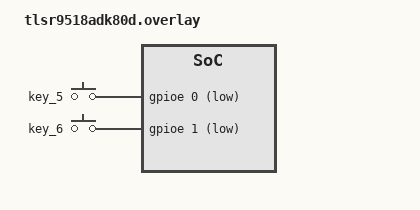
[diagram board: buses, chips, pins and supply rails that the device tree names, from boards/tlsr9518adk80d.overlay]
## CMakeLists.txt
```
#
#    Copyright (c) 2023-2026 Project CHIP Authors
#
#    Licensed under the Apache License, Version 2.0 (the "License");
#    you may not use this file except in compliance with the License.
#    You may obtain a copy of the License at
#
#        http://www.apache.org/licenses/LICENSE-2.0
#
#    Unless required by applicable law or agreed to in writing, software
#    distributed under the License is distributed on an "AS IS" BASIS,
#    WITHOUT WARRANTIES OR CONDITIONS OF ANY KIND, either express or implied.
#    See the License for the specific language governing permissions and
#    limitations under the License.
#

cmake_minimum_required(VERSION 3.20)

get_filename_component(CHIP_ROOT ${CMAKE_CURRENT_SOURCE_DIR}/third_party/connectedhomeip REALPATH)
get_filename_component(TELINK_COMMON ${CHIP_ROOT}/examples/platform/telink REALPATH)
get_filename_component(GEN_DIR ${CHIP_ROOT}/zzz_generated/ REALPATH)

include(${TELINK_COMMON}/common.cmake)
include(${CHIP_ROOT}/config/telink/app/enable-gnu-std.cmake)
include(${CHIP_ROOT}/src/app/chip_data_model.cmake)

project(chip-telink-lock-example)

target_include_directories(app PRIVATE
                           include
                           ${GEN_DIR}/app-common
                           ${GEN_DIR}/lock-app
                           ${TELINK_COMMON}/common/include
                           ${TELINK_COMMON}/util/include
                           ${TELINK_COMMON}/app/include
                           ${TELINK_COMMON}/zephyr_ext)

target_sources(app PRIVATE
               src/AppTask.cpp
               src/AliroDelegate.cpp
               src/ZclCallbacks.cpp
               src/LockManager.cpp
               src/LockSettingsStorage.cpp
               ${CHIP_ROOT}/src/app/persistence/DeferredAttributePersistenceProvider.cpp
               ${TELINK_COMMON}/common/src/mainCommon.cpp
               ${TELINK_COMMON}/common/src/AppTaskCommon.cpp
               ${TELINK_COMMON}/util/src/LEDManager.cpp
               ${TELINK_COMMON}/util/src/ButtonManager.cpp
               ${TELINK_COMMON}/util/src/ThreadUtil.cpp
               ${TELINK_COMMON}/util/src/PWMManager.cpp
               ${TELINK_COMMON}/zephyr_ext/zephyr_key_matrix.c
               ${TELINK_COMMON}/zephyr_ext/zephyr_key_pool.c
               ${TELINK_COMMON}/zephyr_ext/zephyr_led_pool.c
               ${TELINK_COMMON}/zephyr_ext/zephyr_pwm_pool.c
               ${TELINK_COMMON}/zephyr_ext/zephyr_ws2812.c
               ${TELINK_COMMON}/zephyr_ext/zephyr_pm_observer.c)

chip_configure_data_model(app
    ZAP_FILE ${CMAKE_CURRENT_SOURCE_DIR}/../lock-common/lock-app.zap
)

if(CONFIG_BOOTLOADER_MCUBOOT)
  target_sources(app PRIVATE ${TELINK_COMMON}/util/src/OTAUtil.cpp)
endif()

if(CONFIG_OPENTHREAD_SNTP_CLIENT)
  target_sources(app PRIVATE
                   ${TELINK_COMMON}/util/src/ThreadTimeSync.cpp)
endif()
```

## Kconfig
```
#
#    Copyright (c) 2023 Project CHIP Authors
#
#    Licensed under the Apache License, Version 2.0 (the "License");
#    you may not use this file except in compliance with the License.
#    You may obtain a copy of the License at
#
#        http://www.apache.org/licenses/LICENSE-2.0
#
#    Unless required by applicable law or agreed to in writing, software
#    distributed under the License is distributed on an "AS IS" BASIS,
#    WITHOUT WARRANTIES OR CONDITIONS OF ANY KIND, either express or implied.
#    See the License for the specific language governing permissions and
#    limitations under the License.
#
mainmenu "Matter Telink Lock Example Application"

if BOARD_TLSR9528A_RETENTION || BOARD_TLSR9518ADK80D_RETENTION
config COMMON_LIBC_MALLOC_ARENA_SIZE
    default 9216
endif

config SETTINGS_NVS_NAME_CACHE
    default y

config SETTINGS_NVS_NAME_CACHE_SIZE
    default 256

rsource "../../../config/telink/chip-module/Kconfig.defaults"
source "Kconfig.zephyr"
```

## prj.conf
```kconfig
#
#    Copyright (c) 2023-2026 Project CHIP Authors
#
#    Licensed under the Apache License, Version 2.0 (the "License");
#    you may not use this file except in compliance with the License.
#    You may obtain a copy of the License at
#
#        http://www.apache.org/licenses/LICENSE-2.0
#
#    Unless required by applicable law or agreed to in writing, software
#    distributed under the License is distributed on an "AS IS" BASIS,
#    WITHOUT WARRANTIES OR CONDITIONS OF ANY KIND, either express or implied.
#    See the License for the specific language governing permissions and
#    limitations under the License.
#

# This sample uses Kconfig.defaults to set options common for all
# samples. This file should contain only options specific for this sample
# or overrides of default values.

# Enable CHIP
CONFIG_CHIP=y
CONFIG_STD_CPP20=y

# 32774 == 0x8006 (example lock-app)
CONFIG_CHIP_DEVICE_PRODUCT_ID=32774

# Bluetooth Low Energy configuration
CONFIG_BT_DEVICE_NAME="TelinkLock"

# Disable Matter OTA DFU
CONFIG_CHIP_OTA_REQUESTOR=n
CONFIG_CHIP_DEVICE_SOFTWARE_VERSION=1

# Disable CHIP shell support
CONFIG_CHIP_LIB_SHELL=n

# Disable factory data support
CONFIG_CHIP_FACTORY_DATA=n
CONFIG_CHIP_FACTORY_DATA_BUILD=n
CONFIG_CHIP_FACTORY_DATA_MERGE_WITH_FIRMWARE=n

# Enable Power Management
CONFIG_PM=n

# compress ota
CONFIG_COMPRESS_LZMA=n
CONFIG_LZMA=n

# ICD SETTING INFO
CONFIG_CHIP_ICD_SLOW_POLL_INTERVAL=7500
CONFIG_CHIP_ICD_FAST_POLLING_INTERVAL=200
CONFIG_CHIP_ICD_ACTIVE_MODE_THRESHOLD=300
CONFIG_CHIP_ICD_IDLE_MODE_DURATION=900

# Secure programming requires CONFIG_CHIP_FACTORY_DATA and
# CONFIG_CHIP_CERTIFICATION_DECLARATION_STORAGE to be enabled.
CONFIG_SECURE_PROGRAMMING=n

# Enable CHIP-ID via ble
CONFIG_EXPOSE_CHIP_ID_VIA_BLE=n

# Enable Deferred Store Attribute
CONFIG_DEFERRED_ATTR_STORAGE=n
```

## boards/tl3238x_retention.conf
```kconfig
#compress ota
CONFIG_LZMA=y
CONFIG_COMPRESS_LZMA=y
```

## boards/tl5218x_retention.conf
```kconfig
#compress ota
CONFIG_LZMA=n
CONFIG_COMPRESS_LZMA=n

#matter switch mode
# config NORMAL_MODE    0 independent matter mode
# ACTION_DUAL_MODE      1 matter action switch mode ,such as by button
# AUTO_SWITCH_DUAL_MODE 2 matter auto-switch mode ,such as by scan QR code.
CONFIG_DUAL_MODE=0
```

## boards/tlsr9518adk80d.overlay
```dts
/ {
	keys {
		compatible = "gpio-keys";
		key_5: button_5 {
			gpios = <&gpioe 0 (GPIO_PULL_UP | GPIO_ACTIVE_LOW)>;
		};
		key_6: button_6 {
			gpios = <&gpioe 1 (GPIO_PULL_UP | GPIO_ACTIVE_LOW)>;
		};
	};
};

&gpioe {
	interrupts = <38 1>;
	status = "okay";
};
```

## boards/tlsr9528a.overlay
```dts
/ {
	keys {
		compatible = "gpio-keys";
		key_5: button_5 {
			gpios = <&gpiob 6 (GPIO_PULL_UP | GPIO_ACTIVE_LOW)>;
		};
		key_6: button_6 {
			gpios = <&gpiob 7 (GPIO_PULL_UP | GPIO_ACTIVE_LOW)>;
		};
	};
};

&gpiob {
	interrupts = <39 1>;
	status = "okay";
};
```

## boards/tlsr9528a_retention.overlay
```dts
/ {
	keys {
		compatible = "gpio-keys";
		key_5: button_5 {
			gpios = <&gpiob 6 (GPIO_PULL_UP | GPIO_ACTIVE_LOW)>;
		};
		key_6: button_6 {
			gpios = <&gpiob 7 (GPIO_PULL_UP | GPIO_ACTIVE_LOW)>;
		};
	};
};

&gpiob {
	interrupts = <39 1>;
	status = "okay";
};
```

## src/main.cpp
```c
/*
 *
 * SPDX-FileCopyrightText: 2023 Project CHIP Authors
 *
 * SPDX-License-Identifier: Apache-2.0
 */

#include "AppTask.h"

#include <lib/support/CHIPMem.h>
#include <platform/CHIPDeviceLayer.h>

#include <zephyr/kernel.h>

LOG_MODULE_REGISTER(app, CONFIG_CHIP_APP_LOG_LEVEL);

using namespace ::chip;
using namespace ::chip::Inet;
using namespace ::chip::DeviceLayer;

int main(void)
{
    CHIP_ERROR err = CHIP_NO_ERROR;

    err = chip::Platform::MemoryInit();
    if (err != CHIP_NO_ERROR)
    {
        LOG_ERR("MemoryInit fail");
        goto exit;
    }

    err = PlatformMgr().InitChipStack();
    if (err != CHIP_NO_ERROR)
    {
        LOG_ERR("InitChipStack fail");
        goto exit;
    }

    err = PlatformMgr().StartEventLoopTask();
    if (err != CHIP_NO_ERROR)
    {
        LOG_ERR("StartEventLoopTask fail");
        goto exit;
    }

    err = ThreadStackMgr().InitThreadStack();
    if (err != CHIP_NO_ERROR)
    {
        LOG_ERR("InitThreadStack fail");
        goto exit;
    }

#ifdef CONFIG_OPENTHREAD_MTD_SED
    err = ConnectivityMgr().SetThreadDeviceType(ConnectivityManager::kThreadDeviceType_SleepyEndDevice);
#elif CONFIG_OPENTHREAD_MTD
    err = ConnectivityMgr().SetThreadDeviceType(ConnectivityManager::kThreadDeviceType_MinimalEndDevice);
#else
    err = ConnectivityMgr().SetThreadDeviceType(ConnectivityManager::kThreadDeviceType_Router);
#endif
    if (err != CHIP_NO_ERROR)
    {
        LOG_ERR("SetThreadDeviceType fail");
        goto exit;
    }

    err = GetAppTask().StartApp();

exit:
    LOG_ERR("Exit err %" CHIP_ERROR_FORMAT, err.Format());
    return (err == CHIP_NO_ERROR) ? EXIT_SUCCESS : EXIT_FAILURE;
}
```

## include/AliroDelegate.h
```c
/*
 *
 *    Copyright (c) 2026 Project CHIP Authors
 *    All rights reserved.
 *
 *    Licensed under the Apache License, Version 2.0 (the "License");
 *    you may not use this file except in compliance with the License.
 *    You may obtain a copy of the License at
 *
 *        http://www.apache.org/licenses/LICENSE-2.0
 *
 *    Unless required by applicable law or agreed to in writing, software
 *    distributed under the License is distributed on an "AS IS" BASIS,
 *    WITHOUT WARRANTIES OR CONDITIONS OF ANY KIND, either express or implied.
 *    See the License for the specific language governing permissions and
 *    limitations under the License.
 */

#pragma once

#include <AppConfig.h>
#include <app/clusters/door-lock-server/door-lock-delegate.h>
#include <app/clusters/door-lock-server/door-lock-server.h>

class AliroDelegate : public chip::app::Clusters::DoorLock::Delegate
{
public:
    static AliroDelegate & GetInstance() { return sInstance; }

    AliroDelegate(const AliroDelegate &)             = delete;
    AliroDelegate & operator=(const AliroDelegate &) = delete;

    // DoorLock::Delegate interface
    CHIP_ERROR GetAliroReaderVerificationKey(chip::MutableByteSpan & verificationKey) override;
    CHIP_ERROR GetAliroReaderGroupIdentifier(chip::MutableByteSpan & groupIdentifier) override;
    CHIP_ERROR GetAliroReaderGroupSubIdentifier(chip::MutableByteSpan & groupSubIdentifier) override;
    CHIP_ERROR GetAliroExpeditedTransactionSupportedProtocolVersionAtIndex(size_t index,
                                                                           chip::MutableByteSpan & protocolVersion) override;
    CHIP_ERROR GetAliroGroupResolvingKey(chip::MutableByteSpan & groupResolvingKey) override;
    CHIP_ERROR GetAliroSupportedBLEUWBProtocolVersionAtIndex(size_t index, chip::MutableByteSpan & protocolVersion) override;
    uint8_t GetAliroBLEAdvertisingVersion() override;
    uint16_t GetNumberOfAliroCredentialIssuerKeysSupported() override;
    uint16_t GetNumberOfAliroEndpointKeysSupported() override;
    CHIP_ERROR SetAliroReaderConfig(const chip::ByteSpan & signingKey, const chip::ByteSpan & verificationKey,
                                    const chip::ByteSpan & groupIdentifier,
                                    const chip::Optional<chip::ByteSpan> & groupResolvingKey) override;
    CHIP_ERROR ClearAliroReaderConfig() override;

    // Aliro credential storage — called from LockManager
    static bool IsAliroCredentialType(CredentialTypeEnum type);
    bool GetAliroCredential(uint16_t index, CredentialTypeEnum type, EmberAfPluginDoorLockCredentialInfo & out);
    bool SetAliroCredential(uint16_t index, chip::FabricIndex creator, chip::FabricIndex modifier, DlCredentialStatus status,
                            CredentialTypeEnum type, const chip::ByteSpan & data);

private:
    AliroDelegate();

    CHIP_ERROR CopyProtocolVersionIntoSpan(uint16_t protocolVersionValue, chip::MutableByteSpan & protocolVersion);

    // Aliro provisioning state
    uint8_t mAliroReaderVerificationKey[chip::app::Clusters::DoorLock::kAliroReaderVerificationKeySize];
    uint8_t mAliroReaderGroupIdentifier[chip::app::Clusters::DoorLock::kAliroReaderGroupIdentifierSize];
    uint8_t mAliroReaderGroupSubIdentifier[chip::app::Clusters::DoorLock::kAliroReaderGroupSubIdentifierSize];
    uint8_t mAliroGroupResolvingKey[chip::app::Clusters::DoorLock::kAliroGroupResolvingKeySize];
    bool mAliroStateInitialized = false;

    // Aliro credential storage (in-memory; Aliro keys are not persisted to NVM)
    static constexpr size_t kAliroCredentialMaxSize = 65;

    struct CredentialSlot
    {
        DlCredentialStatus status             = DlCredentialStatus::kAvailable;
        chip::FabricIndex createdBy           = 0;
        chip::FabricIndex lastModifiedBy      = 0;
        size_t dataSize                       = 0;
        uint8_t data[kAliroCredentialMaxSize] = { 0 };
    };

    CredentialSlot * SlotArrayForType(CredentialTypeEnum type);

    CredentialSlot mIssuerKeys[APP_MAX_CREDENTIAL];
    CredentialSlot mEvictableEndpointKeys[APP_MAX_CREDENTIAL];
    CredentialSlot mNonEvictableEndpointKeys[APP_MAX_CREDENTIAL];

    static AliroDelegate sInstance;
};
```

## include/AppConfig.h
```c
/*
 *
 *    Copyright (c) 2023 Project CHIP Authors
 *    All rights reserved.
 *
 *    Licensed under the Apache License, Version 2.0 (the "License");
 *    you may not use this file except in compliance with the License.
 *    You may obtain a copy of the License at
 *
 *        http://www.apache.org/licenses/LICENSE-2.0
 *
 *    Unless required by applicable law or agreed to in writing, software
 *    distributed under the License is distributed on an "AS IS" BASIS,
 *    WITHOUT WARRANTIES OR CONDITIONS OF ANY KIND, either express or implied.
 *    See the License for the specific language governing permissions and
 *    limitations under the License.
 */

#pragma once

// ---- Lock Example App Config ----

#define LOCK_MANAGER_CONFIG_USE_NVM_CREDENTIAL_STORAGE 1
#define LOCK_MANAGER_ACTUATOR_MOVEMENT_TIME_MS 2000

#define APP_MAX_USERS 10
#define APP_MAX_CREDENTIAL 10
#define APP_MAX_WEEKDAY_SCHEDULE_PER_USER 10
#define APP_MAX_YEARDAY_SCHEDULE_PER_USER 10
#define APP_MAX_HOLYDAY_SCHEDULE_PER_USER 10

#define APP_MAX_SCHEDULES_TOTAL 100

#define APP_DEFAULT_USERS_COUNT 5
#define APP_DEFAULT_CREDENTIAL_COUNT 5
#define APP_DEFAULT_WEEKDAY_SCHEDULE_PER_USER_COUNT 5
#define APP_DEFAULT_YEARDAY_SCHEDULE_PER_USER_COUNT 5
#define APP_DEFAULT_HOLYDAY_SCHEDULE_PER_USER_COUNT 5

#define APP_SET_NETWORK_COMM_ENDPOINT_SEC 0
```

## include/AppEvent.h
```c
/*
 *
 *    Copyright (c) 2023 Project CHIP Authors
 *    All rights reserved.
 *
 *    Licensed under the Apache License, Version 2.0 (the "License");
 *    you may not use this file except in compliance with the License.
 *    You may obtain a copy of the License at
 *
 *        http://www.apache.org/licenses/LICENSE-2.0
 *
 *    Unless required by applicable law or agreed to in writing, software
 *    distributed under the License is distributed on an "AS IS" BASIS,
 *    WITHOUT WARRANTIES OR CONDITIONS OF ANY KIND, either express or implied.
 *    See the License for the specific language governing permissions and
 *    limitations under the License.
 */

#pragma once

#include <cstdint>

struct AppEvent;
typedef void (*EventHandler)(AppEvent *);

class LEDWidget;

struct AppEvent
{
    enum AppEventTypes
    {
        kEventType_Button = 0,
        kEventType_Timer,
        kEventType_UpdateLedState,
        kEventType_IdentifyStart,
        kEventType_IdentifyStop,
        kEventType_Lighting,
        kEventType_Install,
    };

    uint16_t Type;

    union
    {
        struct
        {
            uint8_t Action;
        } ButtonEvent;
        struct
        {
            void * Context;
        } TimerEvent;
        struct
        {
            LEDWidget * LedWidget;
        } UpdateLedStateEvent;
    };

    EventHandler Handler;
};
```

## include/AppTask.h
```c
/*
 *
 *    Copyright (c) 2023 Project CHIP Authors
 *    All rights reserved.
 *
 *    Licensed under the Apache License, Version 2.0 (the "License");
 *    you may not use this file except in compliance with the License.
 *    You may obtain a copy of the License at
 *
 *        http://www.apache.org/licenses/LICENSE-2.0
 *
 *    Unless required by applicable law or agreed to in writing, software
 *    distributed under the License is distributed on an "AS IS" BASIS,
 *    WITHOUT WARRANTIES OR CONDITIONS OF ANY KIND, either express or implied.
 *    See the License for the specific language governing permissions and
 *    limitations under the License.
 */

#pragma once

#include "AppConfig.h"
#include "AppTaskCommon.h"
#include "LockManager.h"

#define APP_ERROR_EVENT_QUEUE_FAILED CHIP_APPLICATION_ERROR(0x01)
#define APP_ERROR_CREATE_TASK_FAILED CHIP_APPLICATION_ERROR(0x02)
#define APP_ERROR_UNHANDLED_EVENT CHIP_APPLICATION_ERROR(0x03)
#define APP_ERROR_CREATE_TIMER_FAILED CHIP_APPLICATION_ERROR(0x04)
#define APP_ERROR_START_TIMER_FAILED CHIP_APPLICATION_ERROR(0x05)
#define APP_ERROR_STOP_TIMER_FAILED CHIP_APPLICATION_ERROR(0x06)
#define APP_ERROR_ALLOCATION_FAILED CHIP_APPLICATION_ERROR(0x07)

class AppTask : public AppTaskCommon
{
private:
    friend AppTask & GetAppTask(void);
    friend class AppTaskCommon;

    CHIP_ERROR Init(void);
    void LinkButtons(ButtonManager & buttonManager);
    void LinkLeds(LedManager & ledManager);

    static void LockActionEventHandler(AppEvent * event);
    static void LockStateChanged(LockManager::State_t state);
    static void LockJammedEventHandler(void);
    static void LockJammedActionHandler(AppEvent * aEvent);
    static void LockStateEventHandler(void);
    static void LockStateActionHandler(AppEvent * aEvent);

    static AppTask sAppTask;
};

inline AppTask & GetAppTask(void)
{
    return AppTask::sAppTask;
}
```

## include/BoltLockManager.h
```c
/*
 *
 * SPDX-FileCopyrightText: 2023 Project CHIP Authors
 *
 * SPDX-License-Identifier: Apache-2.0
 */

#pragma once

#include <app/clusters/door-lock-server/door-lock-server.h>
#include <lib/core/ClusterEnums.h>
#include <lib/support/ScopedBuffer.h>

#include <zephyr/kernel.h>

#include <cstdint>
#include <vector>

// Maximum number of credentials per user supported by lock
#define CONFIG_LOCK_NUM_CREDENTIALS_PER_USER (2)
// Maximum number of users supported by lock
#define CONFIG_LOCK_NUM_USERS (5)
// Maximum number of credentials supported by lock
#define CONFIG_LOCK_NUM_CREDENTIALS (10)

struct LockCredentialInfo;

#define CONFIG_LOCK_CREDENTIAL_INFO_MAX_DATA_SIZE (20)
#define CONFIG_LOCK_CREDENTIAL_INFO_MAX_TYPES (6)

class AppEvent;

class BoltLockManager
{
public:
    BoltLockManager() :
        mCredentials(CONFIG_LOCK_CREDENTIAL_INFO_MAX_TYPES, std::vector<LockCredentialInfo>(CONFIG_LOCK_NUM_CREDENTIALS + 1))
    {}
    static constexpr size_t kMaxCredentialLength = 128;

    enum class State : uint8_t
    {
        kLockingInitiated = 0,
        kLockingCompleted,
        kUnlockingInitiated,
        kUnlockingCompleted,
    };

    struct UserData
    {
        char mName[DOOR_LOCK_USER_NAME_BUFFER_SIZE];
        CredentialStruct mCredentials[CONFIG_LOCK_NUM_CREDENTIALS_PER_USER];
    };

    struct CredentialData
    {
        chip::Platform::ScopedMemoryBuffer<uint8_t> mSecret;
    };

    using OperationSource     = chip::app::Clusters::DoorLock::OperationSourceEnum;
    using StateChangeCallback = void (*)(State, OperationSource);

    static constexpr uint32_t kActuatorMovementTimeMs = 2000;

    void Init(StateChangeCallback callback);

    State GetState() const { return mState; }
    bool IsLocked() const { return mState == State::kLockingCompleted; }

    bool GetUser(uint16_t userIndex, EmberAfPluginDoorLockUserInfo & user) const;
    bool SetUser(uint16_t userIndex, chip::FabricIndex creator, chip::FabricIndex modifier, const chip::CharSpan & userName,
                 uint32_t uniqueId, UserStatusEnum userStatus, UserTypeEnum userType, CredentialRuleEnum credentialRule,
                 const CredentialStruct * credentials, size_t totalCredentials);

    bool GetCredential(uint16_t credentialIndex, CredentialTypeEnum credentialType,
                       EmberAfPluginDoorLockCredentialInfo & credential) const;
    bool SetCredential(uint16_t credentialIndex, chip::FabricIndex creator, chip::FabricIndex modifier,
                       DlCredentialStatus credentialStatus, CredentialTypeEnum credentialType,
                       const chip::ByteSpan & credentialData);

    bool ValidatePIN(const Optional<chip::ByteSpan> & pinCode, OperationErrorEnum & err) const;

    void Lock(OperationSource source);
    void Unlock(OperationSource source);

private:
    void SetState(State state, OperationSource source);

    static void ActuatorTimerEventHandler(k_timer * timer);
    static void ActuatorAppEventHandler(const AppEvent & aEvent);
    friend BoltLockManager & BoltLockMgr();

    State mState                             = State::kLockingCompleted;
    StateChangeCallback mStateChangeCallback = nullptr;
    OperationSource mActuatorOperationSource = OperationSource::kButton;
    k_timer mActuatorTimer                   = {};

    UserData mUserData[CONFIG_LOCK_NUM_USERS];
    EmberAfPluginDoorLockUserInfo mUsers[CONFIG_LOCK_NUM_USERS] = {};

    struct LockCredentialInfo
    {
        DlCredentialStatus status;
        CredentialTypeEnum credentialType;
        chip::FabricIndex createdBy;
        chip::FabricIndex modifiedBy;
        uint8_t credentialData[CONFIG_LOCK_CREDENTIAL_INFO_MAX_TYPES];
        size_t credentialDataSize;
    };
    std::vector<std::vector<LockCredentialInfo>> mCredentials;

    static BoltLockManager sLock;
};

inline BoltLockManager & BoltLockMgr()
{
    return BoltLockManager::sLock;
}
```

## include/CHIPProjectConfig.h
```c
/*
 *
 *    Copyright (c) 2023 Project CHIP Authors
 *    All rights reserved.
 *
 *    Licensed under the Apache License, Version 2.0 (the "License");
 *    you may not use this file except in compliance with the License.
 *    You may obtain a copy of the License at
 *
 *        http://www.apache.org/licenses/LICENSE-2.0
 *
 *    Unless required by applicable law or agreed to in writing, software
 *    distributed under the License is distributed on an "AS IS" BASIS,
 *    WITHOUT WARRANTIES OR CONDITIONS OF ANY KIND, either express or implied.
 *    See the License for the specific language governing permissions and
 *    limitations under the License.
 */

/**
 *    @file
 *          Example project configuration file for CHIP.
 *
 *          This is a place to put application or project-specific overrides
 *          to the default configuration values for general CHIP features.
 *
 */

#pragma once

// Use a default pairing code if one hasn't been provisioned in flash.
#define CHIP_DEVICE_CONFIG_USE_TEST_SETUP_PIN_CODE 20202021
#define CHIP_DEVICE_CONFIG_USE_TEST_SETUP_DISCRIMINATOR 0xF00

// Enable `Extension` attribute of ACL Cluster as required by door locks
#define CHIP_CONFIG_ENABLE_ACL_EXTENSIONS 1
```

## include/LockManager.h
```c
/*
 *
 *    Copyright (c) 2023 Project CHIP Authors
 *    All rights reserved.
 *
 *    Licensed under the Apache License, Version 2.0 (the "License");
 *    you may not use this file except in compliance with the License.
 *    You may obtain a copy of the License at
 *
 *        http://www.apache.org/licenses/LICENSE-2.0
 *
 *    Unless required by applicable law or agreed to in writing, software
 *    distributed under the License is distributed on an "AS IS" BASIS,
 *    WITHOUT WARRANTIES OR CONDITIONS OF ANY KIND, either express or implied.
 *    See the License for the specific language governing permissions and
 *    limitations under the License.
 */

#pragma once
#include <app/clusters/door-lock-server/door-lock-server.h>

#include <stdbool.h>
#include <stdint.h>
#include <zephyr/kernel.h>

#include <AppConfig.h>
#include <AppEventCommon.h>

#include <lib/core/CHIPError.h>

struct WeekDaysScheduleInfo
{
    DlScheduleStatus status = DlScheduleStatus::kAvailable;
    EmberAfPluginDoorLockWeekDaySchedule schedule;
};

struct YearDayScheduleInfo
{
    DlScheduleStatus status = DlScheduleStatus::kAvailable;
    EmberAfPluginDoorLockYearDaySchedule schedule;
};

struct HolidayScheduleInfo
{
    DlScheduleStatus status = DlScheduleStatus::kAvailable;
    EmberAfPluginDoorLockHolidaySchedule schedule;
};

namespace TelinkDoorLock {
namespace ResourceRanges {
// Used to size arrays
static constexpr uint8_t kMaxCredentialSize  = 20;
static constexpr uint8_t kNumCredentialTypes = 6;

} // namespace ResourceRanges

namespace LockInitParams {

struct LockParam
{
    // Read from zap attributes
    uint16_t numberOfUsers                  = 0;
    uint8_t numberOfCredentialsPerUser      = 0;
    uint8_t numberOfWeekdaySchedulesPerUser = 0;
    uint8_t numberOfYeardaySchedulesPerUser = 0;
    uint8_t numberOfHolidaySchedules        = 0;
};

class ParamBuilder
{
public:
    ParamBuilder & SetNumberOfUsers(uint16_t numberOfUsers)
    {
        lockParam_.numberOfUsers = numberOfUsers;
        return *this;
    }
    ParamBuilder & SetNumberOfCredentialsPerUser(uint8_t numberOfCredentialsPerUser)
    {
        lockParam_.numberOfCredentialsPerUser = numberOfCredentialsPerUser;
        return *this;
    }
    ParamBuilder & SetNumberOfWeekdaySchedulesPerUser(uint8_t numberOfWeekdaySchedulesPerUser)
    {
        lockParam_.numberOfWeekdaySchedulesPerUser = numberOfWeekdaySchedulesPerUser;
        return *this;
    }
    ParamBuilder & SetNumberOfYeardaySchedulesPerUser(uint8_t numberOfYeardaySchedulesPerUser)
    {
        lockParam_.numberOfYeardaySchedulesPerUser = numberOfYeardaySchedulesPerUser;
        return *this;
    }
    ParamBuilder & SetNumberOfHolidaySchedules(uint8_t numberOfHolidaySchedules)
    {
        lockParam_.numberOfHolidaySchedules = numberOfHolidaySchedules;
        return *this;
    }
    LockParam GetLockParam() { return lockParam_; }

private:
    LockParam lockParam_;
};

} // namespace LockInitParams
} // namespace TelinkDoorLock

using namespace ::chip;
using namespace TelinkDoorLock::ResourceRanges;

class LockManager
{
public:
    enum Action_t
    {
        LOCK_ACTION = 0,
        UNLOCK_ACTION,
        UNBOLT_ACTION,

        INVALID_ACTION
    } Action;

    enum State_t
    {
        kState_LockInitiated = 0,
        kState_LockCompleted,
        kState_UnlockInitiated,
        kState_UnlockCompleted,
        kState_UnlatchInitiated,
        kState_UnlatchCompleted,
        kState_NotFulyLocked
    } State;

    using StateChangeCallback = void (*)(State_t);
    using OperationSource     = chip::app::Clusters::DoorLock::OperationSourceEnum;

    CHIP_ERROR Init(chip::app::DataModel::Nullable<chip::app::Clusters::DoorLock::DlLockState> state,
                    TelinkDoorLock::LockInitParams::LockParam lockParam, StateChangeCallback callback);

    bool LockAction(int32_t appSource, Action_t aAction, OperationSource source, chip::EndpointId endpointId);

    bool LockAction(int32_t appSource, Action_t aAction, OperationSource source, chip::EndpointId endpointId,
                    OperationErrorEnum & err, const Nullable<chip::FabricIndex> & fabricIdx = NullNullable,
                    const Nullable<chip::NodeId> & nodeId = NullNullable, const Optional<chip::ByteSpan> & pinCode = NullNullable);

    bool IsLocked() const { return mState == State_t::kState_LockCompleted; }

    State_t getLockState() { return mState; }

    bool GetUser(chip::EndpointId endpointId, uint16_t userIndex, EmberAfPluginDoorLockUserInfo & user);
    bool SetUser(chip::EndpointId endpointId, uint16_t userIndex, chip::FabricIndex creator, chip::FabricIndex modifier,
                 const chip::CharSpan & userName, uint32_t uniqueId, UserStatusEnum userStatus, UserTypeEnum usertype,
                 CredentialRuleEnum credentialRule, const CredentialStruct * credentials, size_t totalCredentials);

    bool GetCredential(chip::EndpointId endpointId, uint16_t credentialIndex, CredentialTypeEnum credentialType,
                       EmberAfPluginDoorLockCredentialInfo & credential);

    bool SetCredential(chip::EndpointId endpointId, uint16_t credentialIndex, chip::FabricIndex creator, chip::FabricIndex modifier,
                       DlCredentialStatus credentialStatus, CredentialTypeEnum credentialType,
                       const chip::ByteSpan & credentialData);

    DlStatus GetWeekdaySchedule(chip::EndpointId endpointId, uint8_t weekdayIndex, uint16_t userIndex,
                                EmberAfPluginDoorLockWeekDaySchedule & schedule);

    DlStatus SetWeekdaySchedule(chip::EndpointId endpointId, uint8_t weekdayIndex, uint16_t userIndex, DlScheduleStatus status,
                                DaysMaskMap daysMask, uint8_t startHour, uint8_t startMinute, uint8_t endHour, uint8_t endMinute);

    DlStatus GetYeardaySchedule(chip::EndpointId endpointId, uint8_t yearDayIndex, uint16_t userIndex,
                                EmberAfPluginDoorLockYearDaySchedule & schedule);

    DlStatus SetYeardaySchedule(chip::EndpointId endpointId, uint8_t yearDayIndex, uint16_t userIndex, DlScheduleStatus status,
                                uint32_t localStartTime, uint32_t localEndTime);

    DlStatus GetHolidaySchedule(chip::EndpointId endpointId, uint8_t holidayIndex, EmberAfPluginDoorLockHolidaySchedule & schedule);

    DlStatus SetHolidaySchedule(chip::EndpointId endpointId, uint8_t holidayIndex, DlScheduleStatus status, uint32_t localStartTime,
                                uint32_t localEndTime, OperatingModeEnum operatingMode);

    bool IsValidUserIndex(uint16_t userIndex);
    bool IsValidCredentialIndex(uint16_t credentialIndex, CredentialTypeEnum type);
    bool IsValidCredentialType(CredentialTypeEnum type);
    bool IsValidWeekdayScheduleIndex(uint8_t scheduleIndex);
    bool IsValidYeardayScheduleIndex(uint8_t scheduleIndex);
    bool IsValidHolidayScheduleIndex(uint8_t scheduleIndex);

    const char * lockStateToString(DlLockState lockState) const;

private:
    friend LockManager & LockMgr();
    State_t mState                           = kState_NotFulyLocked;
    StateChangeCallback mStateChangeCallback = nullptr;
    OperationSource mActuatorOperationSource = OperationSource::kButton;
    k_timer mActuatorTimer                   = {};

    bool setLockState(chip::EndpointId endpointId, DlLockState lockState, OperationSource source, OperationErrorEnum & err,
                      const Nullable<chip::FabricIndex> & fabricIdx, const Nullable<chip::NodeId> & nodeId,
                      const Optional<chip::ByteSpan> & pin);

    static void ActuatorTimerEventHandler(k_timer * timer);
    static void ActuatorAppEventHandler(const AppEvent & event);

#if !LOCK_MANAGER_CONFIG_USE_NVM_CREDENTIAL_STORAGE
    EmberAfPluginDoorLockUserInfo mLockUsers[APP_MAX_USERS];
    EmberAfPluginDoorLockCredentialInfo mLockCredentials[kNumCredentialTypes][APP_MAX_CREDENTIAL];
    WeekDaysScheduleInfo mWeekdaySchedule[APP_MAX_USERS][APP_MAX_WEEKDAY_SCHEDULE_PER_USER];
    YearDayScheduleInfo mYeardaySchedule[APP_MAX_USERS][APP_MAX_YEARDAY_SCHEDULE_PER_USER];
    HolidayScheduleInfo mHolidaySchedule[APP_MAX_HOLYDAY_SCHEDULE_PER_USER];

    char mUserNames[MATTER_ARRAY_SIZE(mLockUsers)][DOOR_LOCK_MAX_USER_NAME_SIZE];
    uint8_t mCredentialData[kNumCredentialTypes][APP_MAX_CREDENTIAL][kMaxCredentialSize];
    CredentialStruct mCredentials[APP_MAX_USERS][APP_MAX_CREDENTIAL];
#endif

    static LockManager sLock;
    TelinkDoorLock::LockInitParams::LockParam LockParams;
};

inline LockManager & LockMgr()
{
    return LockManager::sLock;
}
```

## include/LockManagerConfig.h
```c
/*
 *
 *    Copyright (c) 2023 Project CHIP Authors
 *    All rights reserved.
 *
 *    Licensed under the Apache License, Version 2.0 (the "License");
 *    you may not use this file except in compliance with the License.
 *    You may obtain a copy of the License at
 *
 *        http://www.apache.org/licenses/LICENSE-2.0
 *
 *    Unless required by applicable law or agreed to in writing, software
 *    distributed under the License is distributed on an "AS IS" BASIS,
 *    WITHOUT WARRANTIES OR CONDITIONS OF ANY KIND, either express or implied.
 *    See the License for the specific language governing permissions and
 *    limitations under the License.
 */

#define LOCK_MANAGER_CONFIG_USE_NVM_CREDENTIAL_STORAGE  0
```

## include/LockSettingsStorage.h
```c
/*
 *
 *    Copyright (c) 2023 Project CHIP Authors
 *    All rights reserved.
 *
 *    Licensed under the Apache License, Version 2.0 (the "License");
 *    you may not use this file except in compliance with the License.
 *    You may obtain a copy of the License at
 *
 *        http://www.apache.org/licenses/LICENSE-2.0
 *
 *    Unless required by applicable law or agreed to in writing, software
 *    distributed under the License is distributed on an "AS IS" BASIS,
 *    WITHOUT WARRANTIES OR CONDITIONS OF ANY KIND, either express or implied.
 *    See the License for the specific language governing permissions and
 *    limitations under the License.
 */

#include <../Zephyr/ZephyrConfig.h>
#include <AppConfig.h>
#include <LockManager.h>

#if LOCK_MANAGER_CONFIG_USE_NVM_CREDENTIAL_STORAGE
namespace chip {
namespace DeviceLayer {
namespace Internal {

class LockSettingsStorage : ZephyrConfig
{
public:
    static const char * kConfigKey_LockUser[APP_MAX_USERS];
    static const char * kConfigKey_LockUserName[APP_MAX_USERS];
    static const char * kConfigKey_UserCredentials[APP_MAX_CREDENTIAL];
    static const char * kConfigKey_WeekDaySchedules[APP_MAX_USERS][APP_MAX_WEEKDAY_SCHEDULE_PER_USER];
    static const char * kConfigKey_YearDaySchedules[APP_MAX_USERS][APP_MAX_YEARDAY_SCHEDULE_PER_USER];
    static const char * kConfigKey_HolidaySchedules[APP_MAX_HOLYDAY_SCHEDULE_PER_USER];

    static const char * kConfigKey_CredentialPin[APP_MAX_CREDENTIAL];
    static const char * kConfigKey_CredentialFace[APP_MAX_CREDENTIAL];
    static const char * kConfigKey_CredentialFingerprint[APP_MAX_CREDENTIAL];
    static const char * kConfigKey_CredentialFingervein[APP_MAX_CREDENTIAL];
    static const char * kConfigKey_CredentialRfid[APP_MAX_CREDENTIAL];

    static const char * kConfigKey_CredentialData[APP_MAX_CREDENTIAL];
    static const char * kConfigKey_CredentialDataPin[APP_MAX_CREDENTIAL];
    static const char * kConfigKey_CredentialDataFace[APP_MAX_CREDENTIAL];
    static const char * kConfigKey_CredentialDataFingerprint[APP_MAX_CREDENTIAL];
    static const char * kConfigKey_CredentialDataFingerVein[APP_MAX_CREDENTIAL];
    static const char * kConfigKey_CredentialDataRfid[APP_MAX_CREDENTIAL];
};
} // namespace Internal
} // namespace DeviceLayer
} // namespace chip

#endif
```

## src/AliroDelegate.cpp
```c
/*
 *
 *    Copyright (c) 2026 Project CHIP Authors
 *    All rights reserved.
 *
 *    Licensed under the Apache License, Version 2.0 (the "License");
 *    you may not use this file except in compliance with the License.
 *    You may obtain a copy of the License at
 *
 *        http://www.apache.org/licenses/LICENSE-2.0
 *
 *    Unless required by applicable law or agreed to in writing, software
 *    distributed under the License is distributed on an "AS IS" BASIS,
 *    WITHOUT WARRANTIES OR CONDITIONS OF ANY KIND, either express or implied.
 *    See the License for the specific language governing permissions and
 *    limitations under the License.
 */

#include "AliroDelegate.h"

#include <crypto/CHIPCryptoPAL.h>
#include <lib/core/CHIPEncoding.h>
#include <lib/support/Span.h>
#include <lib/support/logging/CHIPLogging.h>

using namespace chip;
using namespace chip::app::Clusters::DoorLock;

AliroDelegate AliroDelegate::sInstance;

AliroDelegate::AliroDelegate()
{
    CHIP_ERROR err = Crypto::DRBG_get_bytes(mAliroReaderGroupSubIdentifier, sizeof(mAliroReaderGroupSubIdentifier));

    if (err != CHIP_NO_ERROR)
    {
        ChipLogError(Zcl, "Failed to init Aliro sub-identifier: %" CHIP_ERROR_FORMAT, err.Format());
    }
}

// ---------------------------------------------------------------------------
// DoorLock::Delegate — Aliro provisioning attributes
// ---------------------------------------------------------------------------

CHIP_ERROR AliroDelegate::GetAliroReaderVerificationKey(MutableByteSpan & verificationKey)
{
    if (!mAliroStateInitialized)
    {
        verificationKey.reduce_size(0);
        return CHIP_NO_ERROR;
    }

    return CopySpanToMutableSpan(ByteSpan(mAliroReaderVerificationKey), verificationKey);
}

CHIP_ERROR AliroDelegate::GetAliroReaderGroupIdentifier(MutableByteSpan & groupIdentifier)
{
    if (!mAliroStateInitialized)
    {
        groupIdentifier.reduce_size(0);
        return CHIP_NO_ERROR;
    }

    return CopySpanToMutableSpan(ByteSpan(mAliroReaderGroupIdentifier), groupIdentifier);
}

CHIP_ERROR AliroDelegate::GetAliroReaderGroupSubIdentifier(MutableByteSpan & groupSubIdentifier)
{
    return CopySpanToMutableSpan(ByteSpan(mAliroReaderGroupSubIdentifier), groupSubIdentifier);
}

CHIP_ERROR AliroDelegate::CopyProtocolVersionIntoSpan(uint16_t protocolVersionValue, MutableByteSpan & protocolVersion)
{
    static_assert(sizeof(protocolVersionValue) == kAliroProtocolVersionSize);

    if (protocolVersion.size() < kAliroProtocolVersionSize)
    {
        return CHIP_ERROR_INVALID_ARGUMENT;
    }

    // Per Aliro spec, protocol version encoding is big-endian.
    Encoding::BigEndian::Put16(protocolVersion.data(), protocolVersionValue);
    protocolVersion.reduce_size(kAliroProtocolVersionSize);
    return CHIP_NO_ERROR;
}

CHIP_ERROR AliroDelegate::GetAliroExpeditedTransactionSupportedProtocolVersionAtIndex(size_t index,
                                                                                      MutableByteSpan & protocolVersion)
{
    // Only claim support for the one known protocol version for now: 0x0100.
    constexpr uint16_t knownProtocolVersion = 0x0100;

    if (index > 0)
    {
        return CHIP_ERROR_PROVIDER_LIST_EXHAUSTED;
    }

    return CopyProtocolVersionIntoSpan(knownProtocolVersion, protocolVersion);
}

CHIP_ERROR AliroDelegate::GetAliroGroupResolvingKey(MutableByteSpan & groupResolvingKey)
{
    if (!mAliroStateInitialized)
    {
        groupResolvingKey.reduce_size(0);
        return CHIP_NO_ERROR;
    }

    return CopySpanToMutableSpan(ByteSpan(mAliroGroupResolvingKey), groupResolvingKey);
}

CHIP_ERROR AliroDelegate::GetAliroSupportedBLEUWBProtocolVersionAtIndex(size_t index, MutableByteSpan & protocolVersion)
{
    // Only claim support for the one known protocol version for now: 0x0100.
    constexpr uint16_t knownProtocolVersion = 0x0100;

    if (index > 0)
    {
        return CHIP_ERROR_PROVIDER_LIST_EXHAUSTED;
    }

    return CopyProtocolVersionIntoSpan(knownProtocolVersion, protocolVersion);
}

uint8_t AliroDelegate::GetAliroBLEAdvertisingVersion()
{
    // For now the only defined value of the BLE advertising version for Aliro is 0.
    return 0;
}

uint16_t AliroDelegate::GetNumberOfAliroCredentialIssuerKeysSupported()
{
    return APP_MAX_CREDENTIAL;
}

uint16_t AliroDelegate::GetNumberOfAliroEndpointKeysSupported()
{
    return APP_MAX_CREDENTIAL;
}

CHIP_ERROR AliroDelegate::SetAliroReaderConfig(const ByteSpan & signingKey, const ByteSpan & verificationKey,
                                               const ByteSpan & groupIdentifier, const Optional<ByteSpan> & groupResolvingKey)
{
    // We ignore the signing key, since we never do anything with it.
    (void) signingKey;

    VerifyOrReturnError(verificationKey.size() == sizeof(mAliroReaderVerificationKey), CHIP_ERROR_INVALID_ARGUMENT);
    memcpy(mAliroReaderVerificationKey, verificationKey.data(), sizeof(mAliroReaderVerificationKey));

    VerifyOrReturnError(groupIdentifier.size() == sizeof(mAliroReaderGroupIdentifier), CHIP_ERROR_INVALID_ARGUMENT);
    memcpy(mAliroReaderGroupIdentifier, groupIdentifier.data(), sizeof(mAliroReaderGroupIdentifier));

    if (groupResolvingKey.HasValue())
    {
        VerifyOrReturnError(groupResolvingKey.Value().size() == sizeof(mAliroGroupResolvingKey), CHIP_ERROR_INVALID_ARGUMENT);
        memcpy(mAliroGroupResolvingKey, groupResolvingKey.Value().data(), sizeof(mAliroGroupResolvingKey));
    }

    mAliroStateInitialized = true;
    return CHIP_NO_ERROR;
}

CHIP_ERROR AliroDelegate::ClearAliroReaderConfig()
{
    // A real implementation would clear out key data from persistent storage.
    mAliroStateInitialized = false;
    return CHIP_NO_ERROR;
}

// ---------------------------------------------------------------------------
// Aliro credential storage
// ---------------------------------------------------------------------------

/* static */ bool AliroDelegate::IsAliroCredentialType(CredentialTypeEnum type)
{
    switch (type)
    {
    case CredentialTypeEnum::kAliroCredentialIssuerKey:
    case CredentialTypeEnum::kAliroEvictableEndpointKey:
    case CredentialTypeEnum::kAliroNonEvictableEndpointKey:
        return true;
    default:
        return false;
    }
}

AliroDelegate::CredentialSlot * AliroDelegate::SlotArrayForType(CredentialTypeEnum type)
{
    switch (type)
    {
    case CredentialTypeEnum::kAliroCredentialIssuerKey:
        return mIssuerKeys;
    case CredentialTypeEnum::kAliroEvictableEndpointKey:
        return mEvictableEndpointKeys;
    case CredentialTypeEnum::kAliroNonEvictableEndpointKey:
        return mNonEvictableEndpointKeys;
    default:
        return nullptr;
    }
}

bool AliroDelegate::GetAliroCredential(uint16_t index, CredentialTypeEnum type, EmberAfPluginDoorLockCredentialInfo & out)
{
    const CredentialSlot * slots = SlotArrayForType(type);
    VerifyOrReturnValue(slots != nullptr, false);

    auto & slot = slots[index];

    out.status             = slot.status;
    out.credentialType     = type;
    out.createdBy          = slot.createdBy;
    out.lastModifiedBy     = slot.lastModifiedBy;
    out.creationSource     = DlAssetSource::kMatterIM;
    out.modificationSource = DlAssetSource::kMatterIM;
    out.credentialData     = chip::ByteSpan{ slot.data, slot.dataSize };

    ChipLogProgress(Zcl, "AliroDelegate::GetAliroCredential [type=%u,index=%u,status=%d]", to_underlying(type), index,
                    (int) slot.status);

    return true;
}

bool AliroDelegate::SetAliroCredential(uint16_t index, chip::FabricIndex creator, chip::FabricIndex modifier,
                                       DlCredentialStatus status, CredentialTypeEnum type, const chip::ByteSpan & data)
{
    CredentialSlot * slots = SlotArrayForType(type);
    VerifyOrReturnValue(slots != nullptr, false);

    auto & slot = slots[index];

    if (status == DlCredentialStatus::kAvailable)
    {
        slot.status         = DlCredentialStatus::kAvailable;
        slot.dataSize       = 0;
        slot.createdBy      = creator;
        slot.lastModifiedBy = modifier;
        return true;
    }

    VerifyOrReturnValue(data.size() <= kAliroCredentialMaxSize, false);

    memcpy(slot.data, data.data(), data.size());
    slot.dataSize       = data.size();
    slot.status         = status;
    slot.createdBy      = creator;
    slot.lastModifiedBy = modifier;

    ChipLogProgress(Zcl, "AliroDelegate::SetAliroCredential [type=%u,index=%u,dataSize=%u]", to_underlying(type), index,
                    static_cast<unsigned int>(data.size()));

    return true;
}
```
